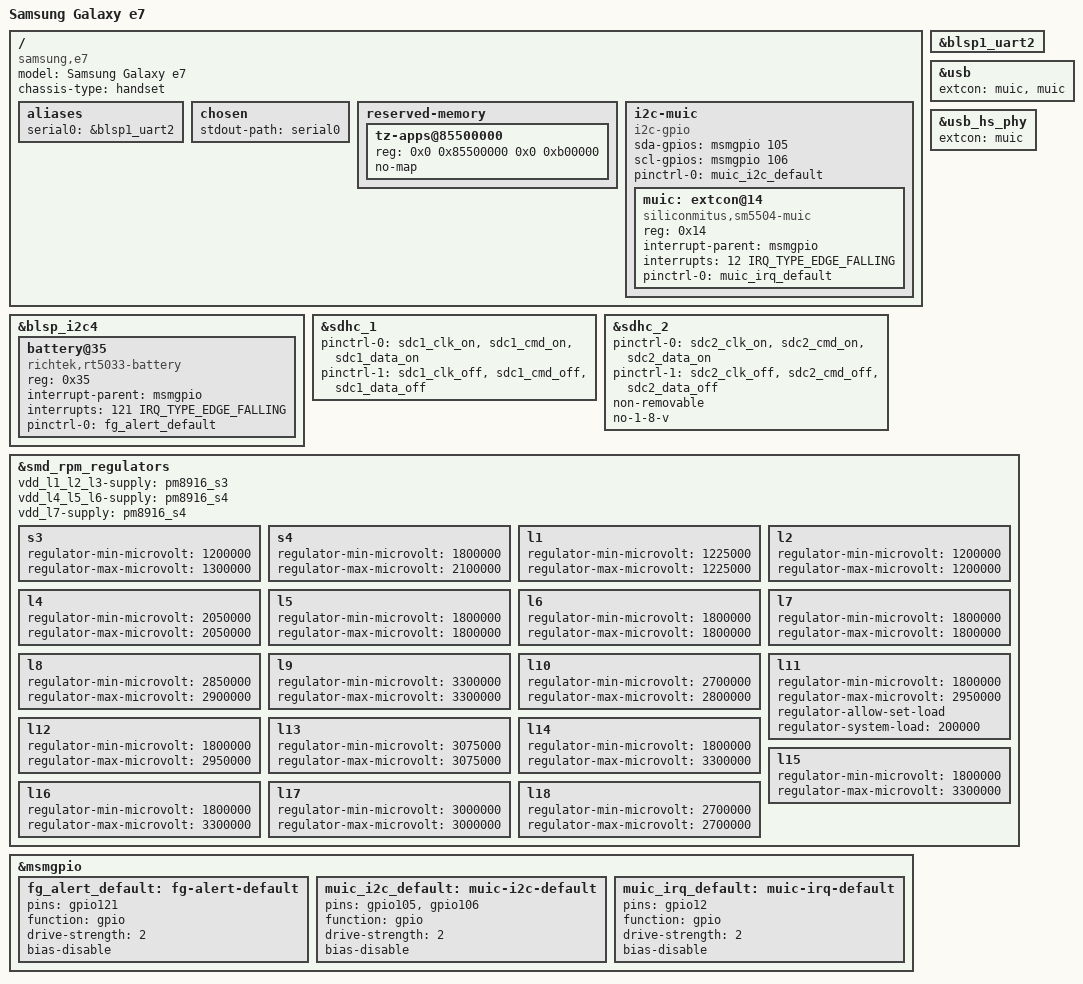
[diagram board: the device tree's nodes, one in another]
// SPDX-License-Identifier: GPL-2.0-only

/dts-v1/;

#include "msm8916-pm8916.dtsi"

#include <dt-bindings/gpio/gpio.h>
#include <dt-bindings/interrupt-controller/irq.h>

/*
 * NOTE: The original firmware from Samsung can only boot ARM32 kernels.
 * Unfortunately, the firmware is signed and cannot be replaced easily.
 * There seems to be no way to boot ARM64 kernels on this device at the moment,
 * even though the hardware would support it.
 *
 * However, it is possible to use this device tree by compiling an ARM32 kernel
 * instead. For clarity and build testing this device tree is maintained next
 * to the other MSM8916 device trees. However, it is actually used through
 *   arch/arm/boot/dts/qcom-msm8916-samsung-e7.dts
 */

/ {
	model = "Samsung Galaxy e7";
	compatible = "samsung,e7", "qcom,msm8916";
	chassis-type = "handset";

	aliases {
		serial0 = &blsp1_uart2;
	};

	chosen {
		stdout-path = "serial0";
	};

	reserved-memory {
		/* Additional memory used by Samsung firmware modifications */
		tz-apps@85500000 {
			reg = <0x0 0x85500000 0x0 0xb00000>;
			no-map;
		};
	};

	i2c-muic {
		compatible = "i2c-gpio";
		sda-gpios = <&msmgpio 105 (GPIO_ACTIVE_HIGH|GPIO_OPEN_DRAIN)>;
		scl-gpios = <&msmgpio 106 (GPIO_ACTIVE_HIGH|GPIO_OPEN_DRAIN)>;

		pinctrl-names = "default";
		pinctrl-0 = <&muic_i2c_default>;

		#address-cells = <1>;
		#size-cells = <0>;

		muic: extcon@14 {
			compatible = "siliconmitus,sm5504-muic";
			reg = <0x14>;

			interrupt-parent = <&msmgpio>;
			interrupts = <12 IRQ_TYPE_EDGE_FALLING>;

			pinctrl-names = "default";
			pinctrl-0 = <&muic_irq_default>;
		};
	};
};

&blsp_i2c4 {
	status = "okay";

	battery@35 {
		compatible = "richtek,rt5033-battery";
		reg = <0x35>;

		interrupt-parent = <&msmgpio>;
		interrupts = <121 IRQ_TYPE_EDGE_FALLING>;

		pinctrl-names = "default";
		pinctrl-0 = <&fg_alert_default>;
	};
};

&blsp1_uart2 {
	status = "okay";
};

&sdhc_1 {
	status = "okay";

	pinctrl-names = "default", "sleep";
	pinctrl-0 = <&sdc1_clk_on &sdc1_cmd_on &sdc1_data_on>;
	pinctrl-1 = <&sdc1_clk_off &sdc1_cmd_off &sdc1_data_off>;
};

&sdhc_2 {
	status = "okay";

	pinctrl-names = "default", "sleep";
	pinctrl-0 = <&sdc2_clk_on &sdc2_cmd_on &sdc2_data_on>;
	pinctrl-1 = <&sdc2_clk_off &sdc2_cmd_off &sdc2_data_off>;

	non-removable;

	/*
	 * FIXME: Disable UHS-I modes since tuning fails with:
	 *
	 * sdhci_msm 7864900.sdhci: mmc1: No tuning point found
	 * mmc1: tuning execution failed: -5
	 * mmc1: error -5 whilst initialising SD card
	 *
	 * This is the quirk used on downstream, which suggests this is
	 * a hardware limitation. However, probing a card using DDR50 works
	 * (without tuning), so maybe only tuning is broken?
	 */
	no-1-8-v;
};

&usb {
	status = "okay";
	extcon = <&muic>, <&muic>;
};

&usb_hs_phy {
	extcon = <&muic>;
};

&smd_rpm_regulators {
	vdd_l1_l2_l3-supply = <&pm8916_s3>;
	vdd_l4_l5_l6-supply = <&pm8916_s4>;
	vdd_l7-supply = <&pm8916_s4>;

	s3 {
		regulator-min-microvolt = <1200000>;
		regulator-max-microvolt = <1300000>;
	};

	s4 {
		regulator-min-microvolt = <1800000>;
		regulator-max-microvolt = <2100000>;
	};

	l1 {
		regulator-min-microvolt = <1225000>;
		regulator-max-microvolt = <1225000>;
	};

	l2 {
		regulator-min-microvolt = <1200000>;
		regulator-max-microvolt = <1200000>;
	};

	l4 {
		regulator-min-microvolt = <2050000>;
		regulator-max-microvolt = <2050000>;
	};

	l5 {
		regulator-min-microvolt = <1800000>;
		regulator-max-microvolt = <1800000>;
	};

	l6 {
		regulator-min-microvolt = <1800000>;
		regulator-max-microvolt = <1800000>;
	};

	l7 {
		regulator-min-microvolt = <1800000>;
		regulator-max-microvolt = <1800000>;
	};

	l8 {
		regulator-min-microvolt = <2850000>;
		regulator-max-microvolt = <2900000>;
	};

	l9 {
		regulator-min-microvolt = <3300000>;
		regulator-max-microvolt = <3300000>;
	};

	l10 {
		regulator-min-microvolt = <2700000>;
		regulator-max-microvolt = <2800000>;
	};

	l11 {
		regulator-min-microvolt = <1800000>;
		regulator-max-microvolt = <2950000>;
		regulator-allow-set-load;
		regulator-system-load = <200000>;
	};

	l12 {
		regulator-min-microvolt = <1800000>;
		regulator-max-microvolt = <2950000>;
	};

	l13 {
		regulator-min-microvolt = <3075000>;
		regulator-max-microvolt = <3075000>;
	};

	l14 {
		regulator-min-microvolt = <1800000>;
		regulator-max-microvolt = <3300000>;
	};

	l15 {
		regulator-min-microvolt = <1800000>;
		regulator-max-microvolt = <3300000>;
	};

	l16 {
		regulator-min-microvolt = <1800000>;
		regulator-max-microvolt = <3300000>;
	};

	l17 {
		regulator-min-microvolt = <3000000>;
		regulator-max-microvolt = <3000000>;
	};

	l18 {
		regulator-min-microvolt = <2700000>;
		regulator-max-microvolt = <2700000>;
	};
};

&msmgpio {
	fg_alert_default: fg-alert-default {
		pins = "gpio121";
		function = "gpio";

		drive-strength = <2>;
		bias-disable;
	};

	muic_i2c_default: muic-i2c-default {
		pins = "gpio105", "gpio106";
		function = "gpio";

		drive-strength = <2>;
		bias-disable;
	};

	muic_irq_default: muic-irq-default {
		pins = "gpio12";
		function = "gpio";

		drive-strength = <2>;
		bias-disable;
	};
};
